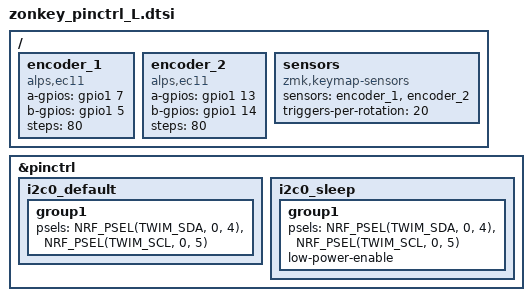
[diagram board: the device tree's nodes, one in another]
&pinctrl {    
    i2c0_default: i2c0_default {
        group1 {
            psels = <NRF_PSEL(TWIM_SDA, 0, 4)>,
                    <NRF_PSEL(TWIM_SCL, 0, 5)>;
            //bias-pull-up;
        };
    };
      
    i2c0_sleep: i2c0_sleep {
        group1 {
            psels = <NRF_PSEL(TWIM_SDA, 0, 4)>,
                    <NRF_PSEL(TWIM_SCL, 0, 5)>;
            low-power-enable;
        };
    };
};

/ {
    encoder_1: encoder_1 {
        compatible = "alps,ec11";
        a-gpios = <&gpio1 7 (GPIO_ACTIVE_HIGH | GPIO_PULL_UP)>;
        b-gpios = <&gpio1 5 (GPIO_ACTIVE_HIGH | GPIO_PULL_UP)>;
        steps = <80>;
        status = "okay";
    };

    encoder_2: encoder_2 {
        compatible = "alps,ec11";
        a-gpios = <&gpio1 13 (GPIO_ACTIVE_HIGH | GPIO_PULL_UP)>;
        b-gpios = <&gpio1 14 (GPIO_ACTIVE_HIGH | GPIO_PULL_UP)>;
        steps = <80>;
        status = "okay";
    };

    sensors: sensors {
        compatible = "zmk,keymap-sensors";
        sensors = <&encoder_1 &encoder_2>;
        triggers-per-rotation = <20>;
    };
};
